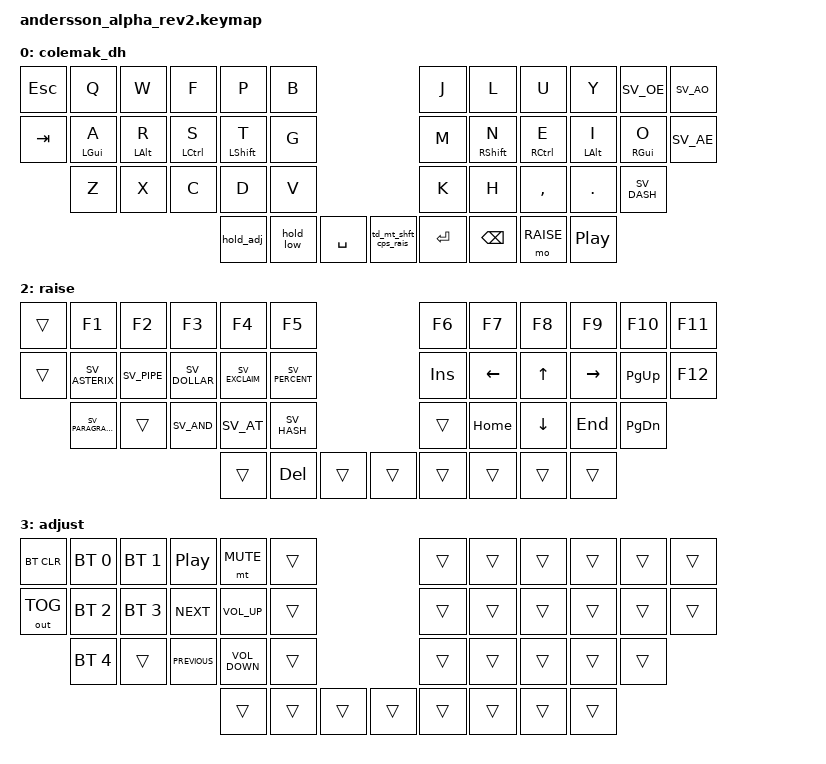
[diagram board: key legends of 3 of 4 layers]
#include <behaviors.dtsi>
#include <dt-bindings/zmk/keys.h>
#include <dt-bindings/zmk/bt.h>
#include <dt-bindings/zmk/outputs.h>

// ! Made for the default Swedish keymap

// Build: west build -b nice_nano_v2 -- -DSHIELD=andersson_alpha_rev2_left

// (
#define SV_LPAR LS(N8)
// )
#define SV_RPAR LS(N9)
// {
#define SV_LBRAC RA(N7)
// }
#define SV_RBRAC RA(N0)
// [
#define SV_LBRAK RA(N8)
// ]
#define SV_RBRAK RA(N9)
// +
#define SV_PLUS MINUS
// ?
#define SV_QUESTION LS(MINUS)
// !
#define SV_EXCLAIM LS(N1)
// å
#define SV_AO LEFT_BRACKET
// ä
#define SV_AE SQT
// ö
#define SV_OE SEMICOLON
// '
#define SV_SINGLEQ BACKSLASH
// "
#define SV_DOUBLEQ LS(N2)
// <
#define SV_LESS NON_US_BACKSLASH
// >
#define SV_GREA LS(NON_US_BACKSLASH)
// /
#define SV_SLASH LS(N7)
// Backslash
#define SV_BACKSLASH RA(MINUS)
// @
#define SV_AT RA(N2)
// &
#define SV_AND LS(N6)
// |
#define SV_PIPE RA(NON_US_BACKSLASH)
// #
#define SV_HASH LS(N3)
// =
#define SV_EQUAL LS(N0)
// %
#define SV_PERCENT LS(N5)
// *
#define SV_ASTERIX LS(BACKSLASH)
// $
#define SV_DOLLAR RA(N4)
// `
#define SV_BACKTICK LS(EQUAL)
// ^
#define SV_EXPONENT LS(RIGHT_BRACKET)
// ~
#define SV_TILDE RA(RIGHT_BRACKET)
// §
#define SV_PARAGRAPH GRAVE
// ´
#define SV_GRAVE EQUAL
// :
#define SV_COLON LS(DOT)
// ;
#define SV_SEMICOLON LS(COMMA)
// -
#define SV_DASH SLASH

#define DEFAULT  0
#define LOWER    1
#define RAISE    2
#define ADJUST   3

/ {
	behaviors {
		hm: homerow_mods {
			compatible = "zmk,behavior-hold-tap";
			label = "homerow mods";
			#binding-cells = <2>;
			tapping_term_ms = <170>;
			flavor = "tap-preferred";
			bindings = <&kp>, <&kp>;
		};

		td_mt_shft_cps_rais: td_mt_shft_cps_rais {
			compatible = "zmk,behavior-tap-dance";
			label = "shift caps adjust";
			#binding-cells = <0>;
			tapping-term-ms = <200>;
			bindings = <&mt LSHIFT CAPSLOCK>, <&mo ADJUST>;
		};

		hold_adj: hold_adj {
			compatible = "zmk,behavior-momentary-layer";
			label = "Hold to ADJUST";
			#binding-cells = <0>;
			bindings = <&mo ADJUST>;
		};

		hold_low: hold_low {
			compatible = "zmk,behavior-momentary-layer";
			label = "Hold to LOWER";
			#binding-cells = <0>;
			bindings = <&mo LOWER>;
		};
	};

	keymap {
		compatible = "zmk,keymap";

		colemak_dh {
			// ----------------------------------------------------------------------------------------------------------------
			// | ESC |  Q  |  W  |  F  |  P  |  B  |                #                  |  J  |  L   |  U   |  Y   |  Ö  |  Å  |
			// | TAB |  A  |  R  |  S  |  T  |  G  |                #                  |  M  |  N   |  E   |  I   |  O  |  Ä  |
			//       |  Z  |  X  |  C  |  D  |  V  |                #                  |  K  |  H   |  ,;  |  .:  |  -  |
			//                         | ADJ | LOW | SPACE | CAPS | # | RETURN | BKSPC | RAI | PLPA |

			bindings = <
&kp ESC  &kp Q       &kp W       &kp F        &kp P         &kp B                                                                  &kp J      &kp L             &kp U        &kp Y       &kp SV_OE    &kp SV_AO
&kp TAB  &hm LGUI A  &hm LALT R  &hm LCTRL S  &hm LSHIFT T  &kp G                                                                  &kp M      &hm RSHIFT N      &hm RCTRL E  &hm LALT I  &hm RGUI O   &kp SV_AE
         &kp Z       &kp X       &kp C        &kp D         &kp V                                                                  &kp K      &kp H             &kp COMMA    &kp DOT     &kp SV_DASH
                                              &hold_adj     &hold_low  &kp SPACE  &td_mt_shft_cps_rais     &kp RET  &kp BACKSPACE  &mo RAISE  &kp C_PLAY_PAUSE
			>;
		};

		lower {
			// --------------------------------------------------------------------------------------------
			// |   |  1  |  2  |  3  |  4   |  5  |         #           |  6  |  7  |  8  |  9  |  0  |   |
			// |   |  ?  |  <  |  (  |  {   |  [  |         #           |  :  |  '  |  /  |  `  |  +  |   |
			// |   |  =  |  >  |  )  |  }   |  ]  |   |   | # |   |     |  ;  |  "  |  \  |  ´  |  -  |   |
			//                 |     | LWIN |     |   |   | # |   | DEL |     |     |     |

			bindings = <
&trans  &kp N1           &kp N2       &kp N3       &kp N4        &kp N5                                             &kp N6            &kp N7          &kp N8            &kp N9           &kp N0       &trans
&trans  &kp SV_QUESTION  &kp SV_LESS  &kp SV_LPAR  &kp SV_LBRAC  &kp SV_LBRAK                                       &kp SV_COLON      &kp SV_SINGLEQ  &kp SV_SLASH      &kp SV_BACKTICK  &kp SV_PLUS  &trans
        &kp SV_EQUAL     &kp SV_GREA  &kp SV_RPAR  &kp SV_RBRAC  &kp SV_RBRAK  &trans  &trans      &trans  &trans   &kp SV_SEMICOLON  &kp SV_DOUBLEQ  &kp SV_BACKSLASH  &kp SV_GRAVE     &kp SV_DASH
                                                   &trans      &trans        &trans  &trans      &trans  &kp DEL  &trans            &trans
			>;
		};

		raise {
			// ------------------------------------------------------------------------------------------------------
			// |   | F1  | F2   | F3  | F4  | F5  |         #               | F6  |  F7  |  F8  |  F9  | F10  | F11 |
			// |   |  *  | pipe |  $  |  !  |  %  |         #               | INS | LARR | UARR | RARR | PGUP | F12 |
			//     |  §  |      |  &  |  @  |  #  |         #               |     | HOME | DARR | END  | PGDN |
			//                        |     | DEL |   |   | # |      |      |     |      |

			bindings = <
&trans  &kp F1            &kp F2       &kp F3         &kp F4          &kp F5                                             &kp F6   &kp F7          &kp F8          &kp F9           &kp F10    &kp F11
&trans  &kp SV_ASTERIX    &kp SV_PIPE  &kp SV_DOLLAR  &kp SV_EXCLAIM  &kp SV_PERCENT                                     &kp INS  &kp LEFT_ARROW  &kp UP_ARROW    &kp RIGHT_ARROW  &kp PG_UP  &kp F12
        &kp SV_PARAGRAPH  &trans       &kp SV_AND     &kp SV_AT       &kp SV_HASH                                        &trans   &kp HOME        &kp DOWN_ARROW  &kp END          &kp PG_DN
                                                      &trans          &kp DEL         &trans  &trans     &trans  &trans  &trans   &trans
			>;
		};

		adjust {
			// -------------------------------------------------------------------------------------------
			// | BT CLR  | BT 0 | BT 1 | PLPA | MUTE |   |             #         |   |   |   |   |   |   |
			// | OUT TGL | BT 2 | BT 3 | NEXT | VOLU |   |             #         |   |   |   |   |   |   |
			//           | BT 4 |      | PREV | VOLD |   |             #         |   |   |   |   |   |
			//                                |      |   |     |     | # |   |   |   |   |

			bindings = <
&bt BT_CLR    &bt BT_SEL 0  &bt BT_SEL 1  &kp C_PLAY_PAUSE  &mt K_MUTE         &trans                                     &trans  &trans  &trans  &trans  &trans  &trans
&out OUT_TOG  &bt BT_SEL 2  &bt BT_SEL 3  &kp C_NEXT        &kp C_VOLUME_UP    &trans                                     &trans  &trans  &trans  &trans  &trans  &trans
              &bt BT_SEL 4  &trans        &kp C_PREVIOUS    &kp C_VOLUME_DOWN  &trans                                     &trans  &trans  &trans  &trans  &trans
                                                            &trans             &trans  &trans  &trans     &trans  &trans  &trans  &trans
			>;
		};
	};

	combos {
		compatible = "zmk,combos";

		combo_super {
			timeout-ms = <50>;
			key-positions = <30 31>;
			bindings = <&kp LGUI>;
			layers = <0>;
		};
	};
};
